# G32R502 register map
Vendor: Geehy Semiconductor Co., Ltd.; Series: G32R5; File version: 1.0
CPU: CM52 r0p1, little endian, MPU, FPU, DSP, VTOR, 4 interrupt priority bits
Registers are 32-bit, read-write, reset 0x0 unless marked. A register's access mark holds for its fields unless they carry their own. Offsets are from the block's base; [hi:lo] are bit positions; {n}, {i} and the like mark numbered series; 'fields as' and 'values as' point back to an identical list.

## CAP1 — Enhanced capture (CAP) module
Base 0x40020400
Same registers: CAP2 0x40020800, CAP3 0x40020C00
0x00 TSCTR — Time-Stamp Counter
  [31:0] TSCTR — Active 32-bit counter register that is used as the capture time-base HR mode
0x04 CTRPHS — Counter Phase Offset Value Register
  [31:0] CTRPHS — Counter phase value register that can be programmed for phase lag/lead
{0x4+4i} CAP{i} (i=1..4) — Capture {i} Register
0x24 ECCTL0 reset 0x7F — Capture Control Register 0
  [6:0] INPUTSEL — Capture input source select bits
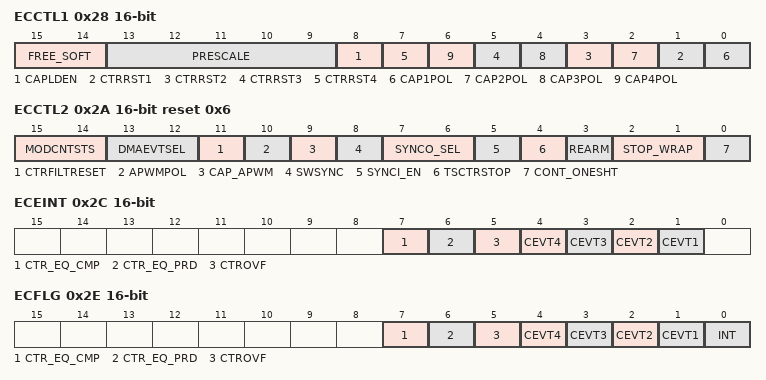
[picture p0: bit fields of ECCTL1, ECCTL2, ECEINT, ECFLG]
0x28 ECCTL1 16-bit — Capture Control Register 1
  [15:14] FREE_SOFT — Emulation Control
  [13:9] PRESCALE — Event Filter prescale select
  [8] CAPLDEN — Enable loading of CAP1-4 registers on a capture event
  [2n-1] CTRRST{n} (n=1..4) — Counter Reset on Capture Event {n}
  [2n-2] CAP{n}POL (n=1..4) — Capture Event {n} Polarity select
0x2A ECCTL2 16-bit access per field reset 0x6 — Capture Control Register 2
  [15:14] MODCNTSTS ro — This bit field reads current status on modulo counter
  [13:12] DMAEVTSEL rw — DMA event select
  [11] CTRFILTRESET rw — Reset Bit
  [10] APWMPOL rw — APWM output polarity select
  [9] CAP_APWM rw — CAP/APWM operating mode select
  [8] SWSYNC rw — Software-forced Counter (TSCTR) Synchronizer
  [7:6] SYNCO_SEL rw — Sync-Out Select
  [5] SYNCI_EN rw — Counter (TSCTR) Sync_In select mode
  [4] TSCTRSTOP rw — Time Stamp (TSCTR) Counter Stop (freeze) Control
  [3] REARM rw — Re-Arming Control
  [2:1] STOP_WRAP rw — Stop value for one-shot mode, Wrap value for continuous
  [0] CONT_ONESHT rw — Continuous or one-sho mode control (applicable only in capture mode)
0x2C ECEINT 16-bit — Capture Interrupt Enable Register
  [7] CTR_EQ_CMP — Counter Equal Compare Interrupt Enable
  [6] CTR_EQ_PRD — Counter Equal Period Interrupt Enable
  [5] CTROVF — Counter Overflow Interrupt Enable
  [n] CEVT{n} (n=1..4) — Capture Event {n} Interrupt Enable
0x2E ECFLG 16-bit ro — Capture Interrupt Flag Register
  [7] CTR_EQ_CMP — Counter Equal Compare Interrupt Flag
  [6] CTR_EQ_PRD — Counter Equal Period Interrupt Flag
  [5] CTROVF — Counter Overflow Interrupt Flag
  [n] CEVT{n} (n=1..4) — Capture Event {n} Interrupt Flag
  [0] INT — Global Interrupt Status Flag
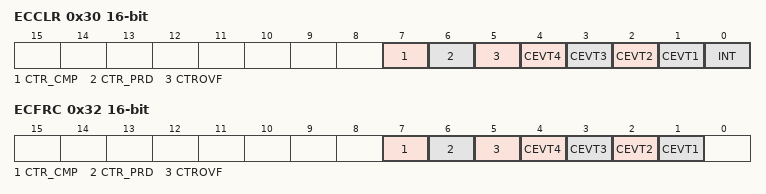
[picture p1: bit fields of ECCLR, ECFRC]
0x30 ECCLR 16-bit — Capture Interrupt Clear Register
  [7] CTR_CMP — Counter Equal Compare Status Clear
  [6] CTR_PRD — Counter Equal Period Status Clear
  [5] CTROVF — Counter Overflow Status Clear
  [n] CEVT{n} (n=1..4) — Capture Event {n} Status Clear
  [0] INT — Global Interrupt Status Clear
0x32 ECFRC 16-bit — Capture Interrupt Force Register
  [7] CTR_CMP — Force Counter Equal Compare Interrupt
  [6] CTR_PRD — Force Capture Event 2
  [5] CTROVF — Force Counter Overflow Interrupt
  [n] CEVT{n} (n=1..4) — Force Capture Event {n} Interrupt
0x3C CAPSYNCINSEL — CAP Sync Input Select Register
  [4:0] SEL — Sync Input Source Select

## COMP1 — Comparator
Base 0x40021000
Same registers: COMP2 0x40021400, COMP3 0x40021800, COMP4 0x40021C00
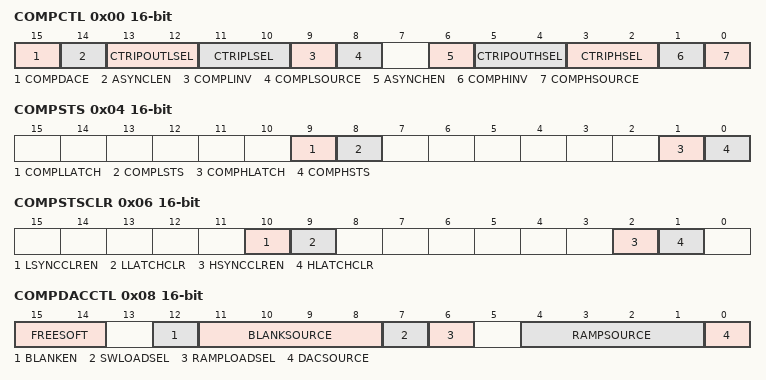
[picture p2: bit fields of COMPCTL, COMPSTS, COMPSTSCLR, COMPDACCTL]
0x00 COMPCTL 16-bit — COMP Comparator Control Register
  [15] COMPDACE — Comparator/DAC Enable
  [14] ASYNCLEN — Low Comparator Asynchronous Path Enable
  [13:12] CTRIPOUTLSEL — Low Comparator Trip Output Select
  [11:10] CTRIPLSEL — Low Comparator Trip Select
  [9] COMPLINV — Low Comparator Invert Select
  [8] COMPLSOURCE — Low Comparator Source Select
  [6] ASYNCHEN — High Comparator Asynchronous Path Enable
  [5:4] CTRIPOUTHSEL — High Comparator Trip Output Select
  [3:2] CTRIPHSEL — High Comparator Trip Select
  [1] COMPHINV — High Comparator Invert Select
  [0] COMPHSOURCE — High Comparator Source Select
0x02 COMPHYSCTL 16-bit — COMP Comparator Hysteresis Control Register
  [3:0] COMPHYS — Comparator Hysteresis Trim
0x04 COMPSTS 16-bit ro — COMP Comparator Status Register
  [9] COMPLLATCH — Low Comparator Latched Status
  [8] COMPLSTS — Low Comparator Status
  [1] COMPHLATCH — High Comparator Latched Status
  [0] COMPHSTS — High Comparator Status
0x06 COMPSTSCLR 16-bit — COMP Comparator Status Clear Register
  [10] LSYNCCLREN — Low Comparator EPWMSYNCPER Clear Enable
  [9] LLATCHCLR — Low Comparator Latched Status Clear
  [2] HSYNCCLREN — High Comparator EPWMSYNCPER Clear Enable
  [1] HLATCHCLR — High Comparator Latched Status Clear
0x08 COMPDACCTL 16-bit — COMP DAC Control Register
  [15:14] FREESOFT — Free/Soft Emulation Bits
  [12] BLANKEN — EPWMBLANK Enable
  [11:8] BLANKSOURCE — EPWMBLANK Source Select
  [7] SWLOADSEL — Software Load Select
  [6] RAMPLOADSEL — Ramp Load Select
  [4:1] RAMPSOURCE — Ramp Generator Source Control
  [0] DACSOURCE — DAC Source Control
0x0C DACHVALS 16-bit — COMP High DAC Value Shadow Register
  [11:0] DACVAL — DAC Value Control
0x0E DACHVALA 16-bit ro — COMP High DAC Value Active Register
  [11:0] DACVAL — DAC Value Control
0x10 RAMPMAXREFA 16-bit ro — COMP Ramp Max Reference Active Register
  [15:0] RAMPMAXREFA — Ramp maximum reference active value
0x14 RAMPMAXREFS 16-bit — COMP Ramp Max Reference Shadow Register
  [15:0] RAMPMAXREFS — Ramp maximum reference shadow value
0x18 RAMPDECVALA 16-bit ro — COMP Ramp Decrement Value Active Register
  [15:0] RAMPDECVALA — Ramp decrement value active
0x1C RAMPDECVALS 16-bit — COMP Ramp Decrement Value Shadow Register
  [15:0] RAMPDECVALS — Ramp decrement value shadow
0x20 RAMPSTS 16-bit ro — COMP Ramp Status Register
  [15:0] RAMPSTS — Ramp value
0x24 DACLVALS 16-bit — COMP Low DAC Value Shadow Register
  [11:0] DACVAL — DAC Value Control
0x26 DACLVALA 16-bit ro — COMP Low DAC Value Active Register
  [11:0] DACVAL — DAC Value Control
0x28 RAMPDLYA 16-bit ro — COMP Ramp Delay Active Register
  [12:0] DELAY — Ramp Delay Value
0x2A RAMPDLYS 16-bit — COMP Ramp Delay Shadow Register
  [12:0] DELAY — Ramp Delay Value
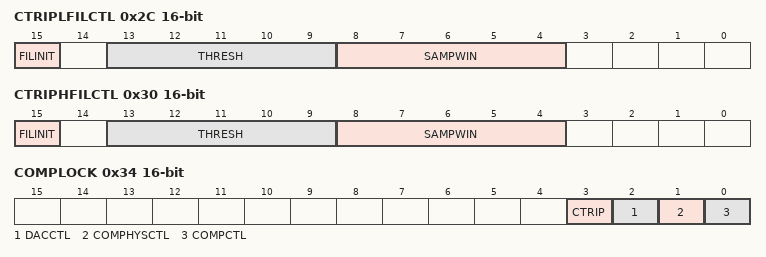
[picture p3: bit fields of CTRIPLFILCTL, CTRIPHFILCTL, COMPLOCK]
0x2C CTRIPLFILCTL 16-bit — CTRIPL Filter Control Register
  [15] FILINIT — Filter Initialization Bit
  [13:9] THRESH — Majority Voting Threshold
  [8:4] SAMPWIN — Sample Window
0x2E CTRIPLFILCLKCTL 16-bit — CTRIPL Filter Clock Control Register
  [9:0] CLKPRESCALE — Sample Clock Prescale
0x30 CTRIPHFILCTL 16-bit — CTRIPH Filter Control Register
  fields as CTRIPLFILCTL
0x32 CTRIPHFILCLKCTL 16-bit — CTRIPH Filter Clock Control Register
  [9:0] CLKPRESCALE — Sample Clock Prescale
0x34 COMPLOCK 16-bit write-once
  [3] CTRIP — CTRIP Lock
  [2] DACCTL — DACCTL Lock
  [1] COMPHYSCTL — COMPHYSCTL Lock
  [0] COMPCTL — COMPCTL Lock
